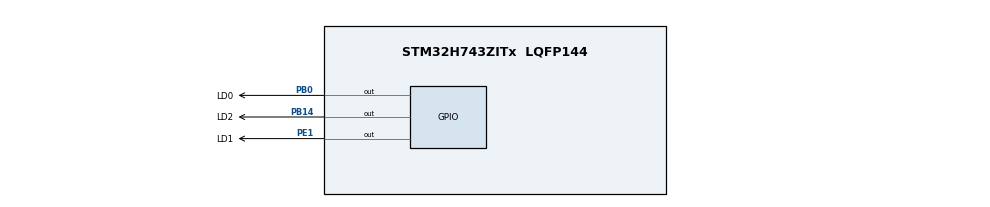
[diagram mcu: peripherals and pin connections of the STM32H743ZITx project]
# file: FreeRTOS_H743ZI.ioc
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Mcu.Family=STM32H7
Mcu.Name=STM32H743ZITx
Mcu.Package=LQFP144
NVIC.PriorityGroup=NVIC_PRIORITYGROUP_4
NVIC.TIM6_DAC_IRQn=true\:0\:0\:false\:true\:true\:2\:true\:true\:true
NVIC.TIM7_IRQn=true\:15\:0\:false\:false\:true\:false\:true\:true
NVIC.TimeBase=TIM7_IRQn
NVIC.TimeBaseIP=TIM7
PB0.GPIO_Label=LD0
PB0.GPIO_Speed=GPIO_SPEED_FREQ_VERY_HIGH
PB0.Signal=GPIO_Output
PB14.GPIO_Label=LD2
PB14.GPIO_Speed=GPIO_SPEED_FREQ_VERY_HIGH
PB14.Signal=GPIO_Output
PD8.Signal=USART3_TX
PD9.Signal=USART3_RX
PE1.GPIO_Label=LD1
PE1.GPIO_Speed=GPIO_SPEED_FREQ_VERY_HIGH
PE1.Signal=GPIO_Output
PH0-OSC_IN\ (PH0).Mode=HSE-External-Clock-Source
PH0-OSC_IN\ (PH0).Signal=RCC_OSC_IN
ProjectManager.HeapSize=0x200
ProjectManager.StackSize=0x400
ProjectManager.TargetToolchain=STM32CubeIDE
RCC.ADCFreq_Value=512000000
RCC.APB1Freq_Value=100000000
RCC.APB2Freq_Value=100000000
RCC.APB3Freq_Value=100000000
RCC.APB4Freq_Value=100000000
RCC.CortexFreq_Value=100000000
RCC.DIVM1=4
RCC.DIVM2=4
RCC.DIVM3=2
RCC.DIVN1=12
RCC.DIVN2=64
RCC.DIVN3=12
RCC.DIVQ3=30
RCC.HCLKFreq_Value=100000000
RCC.HSE_VALUE=25000000
RCC.PLL2FRACN=0
RCC.PLL2_VCI_Range-AdvancedSettings=RCC_PLL2VCIRANGE_3
RCC.PLL3FRACN=0
RCC.PLLFRACN=4096
RCC.PWR_Regulator_Voltage_Scale=PWR_REGULATOR_VOLTAGE_SCALE2
RCC.RCC_TIM_PRescaler_Selection=RCC_TIMPRES_ACTIVATED
RCC.SYSCLKFreq_VALUE=100000000
RCC.SYSCLKSource=RCC_SYSCLKSOURCE_PLLCLK
RCC.USART234578CLockSelection=RCC_USART234578CLKSOURCE_PLL3
RCC.USBFreq_Value=100000000
TIM6.AutoReloadPreload=TIM_AUTORELOAD_PRELOAD_DISABLE
TIM6.Period=100-1
TIM6.Prescaler=1000
VP_SYS_VS_tim7.Mode=TIM7
VP_TIM6_VS_ClockSourceINT.Mode=Enable_Timer
board=custom

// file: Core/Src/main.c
/* USER CODE BEGIN Header */
/**
  ******************************************************************************
  * @file           : main.c
  * @brief          : Main program body
  ******************************************************************************
  * @attention
  *
  * Copyright (c) 2026 STMicroelectronics.
  * All rights reserved.
  *
  * This software is licensed under terms that can be found in the LICENSE file
  * in the root directory of this software component.
  * If no LICENSE file comes with this software, it is provided AS-IS.
  *
  ******************************************************************************
  */
/* USER CODE END Header */
#include "main.h"

TIM_HandleTypeDef htim6;

/* USER CODE BEGIN PV */
#define STACK_SIZE 128

TaskHandle_t task1Handle;
TaskHandle_t task1Handle2;
TaskHandle_t task1Handle3;
/* USER CODE END PV */

void SystemClock_Config(void);
void PeriphCommonClock_Config(void);
static void MX_GPIO_Init(void);
static void MX_TIM6_Init(void);
static void MX_NVIC_Init(void);
/* USER CODE BEGIN PFP */
void vPortSetupTimerInterrupt(void)
{
	// Do not use sysTick timer for freRTOS, Created the timer TIM6 for it.
}
/* USER CODE END PFP */

/* USER CODE BEGIN 0 */
void monitorTask(void *para)
{
	uint8_t val = 0;
	bool Stat = false;
	TimeOut_t RefTimet;
	TickType_t RequiredTimet = 5000;

	vTaskSetTimeOutState(&RefTimet);
  while(1)
  {
	if(xTaskCheckForTimeOut(&RefTimet, &RequiredTimet) == pdTRUE)
	{
		// Timeout occured
		vTaskSetTimeOutState(&RefTimet);
		RequiredTimet = 5000;
	}
	vTaskDelay(pdMS_TO_TICKS(100));
	// Previosly not running because this task was the highest priority and it occupied the total CPU usage by
	// poling for the status "xTaskCheckForTimeOut()". So We added the delay "vTaskDelay" and lets the other
	// tasks occupied the CPU whenever this task is not doing anything. Of course this is the demo code so we can add
	// delay to make things understanding but in actual application we might apply some thing professional.
  }
}

void Task2 (void* para)
{
	BaseType_t delaystate;

	TickType_t tickCount = xTaskGetTickCount();
	while(1)
	{
		delaystate = xTaskDelayUntil(&tickCount, pdMS_TO_TICKS(1000));
		if(delaystate == pdTRUE)
		{
			HAL_GPIO_TogglePin(LD0_GPIO_Port, LD0_Pin);
		}
	}
}

void Task3 (void* para)
{
	BaseType_t delaystate;

	TickType_t tickCount = xTaskGetTickCount();
	while(1)
	{
		delaystate = xTaskDelayUntil(&tickCount, pdMS_TO_TICKS(500));
		if(delaystate == pdTRUE)
		{
			HAL_GPIO_TogglePin(LD1_GPIO_Port, LD1_Pin);
		}
	}
}
//Successfully Ported..
/* USER CODE END 0 */

int main(void)
{

  /* MCU Configuration--------------------------------------------------------*/

  /* Reset of all peripherals, Initializes the Flash interface and the Systick. */
  HAL_Init();

  /* Configure the system clock */
  SystemClock_Config();

/* Configure the peripherals common clocks */
  PeriphCommonClock_Config();

  /* Initialize all configured peripherals */
  MX_GPIO_Init();
  MX_TIM6_Init();

  /* Initialize interrupts */
  MX_NVIC_Init();
  /* USER CODE BEGIN 2 */
#if 1
  if(xTaskCreate(monitorTask,
  			"SampleTask",
  			STACK_SIZE,
  			NULL,
  			tskIDLE_PRIORITY + 4,
  			&task1Handle) == pdFAIL)
  	{
  	// Task created
  		while(1);
  	}

  	if(xTaskCreate(Task2,
  				"Task2",
  				STACK_SIZE,
  				NULL,
  				tskIDLE_PRIORITY + 2,
  				&task1Handle2) == pdFAIL)
  	{
  		while(1);
  	}

  	if(xTaskCreate(Task3,
  				"Task3",
  				STACK_SIZE,
  				NULL,
  				tskIDLE_PRIORITY + 1,
  				&task1Handle3) == pdFAIL)
  	{
  		while(1);
  	}

  	vTaskStartScheduler();
#endif
  /* USER CODE END 2 */

  /* Infinite loop */
  /* USER CODE BEGIN WHILE */
  while (1)
  {
	  //HAL_GPIO_TogglePin(LD0_GPIO_Port, LD0_Pin);
	  //HAL_GPIO_TogglePin(LD1_GPIO_Port, LD1_Pin);
	  //HAL_GPIO_TogglePin(LD2_GPIO_Port, LD2_Pin);
	  HAL_Delay(500);
    /* USER CODE END WHILE */

  }
}

void SystemClock_Config(void)
{
  RCC_OscInitTypeDef RCC_OscInitStruct = {0};
  RCC_ClkInitTypeDef RCC_ClkInitStruct = {0};

  /** Supply configuration update enable
  */
  HAL_PWREx_ConfigSupply(PWR_LDO_SUPPLY);

  /** Configure the main internal regulator output voltage
  */
  __HAL_PWR_VOLTAGESCALING_CONFIG(PWR_REGULATOR_VOLTAGE_SCALE2);

  while(!__HAL_PWR_GET_FLAG(PWR_FLAG_VOSRDY)) {}

  /** Initializes the RCC Oscillators according to the specified parameters
  * in the RCC_OscInitTypeDef structure.
  */
  RCC_OscInitStruct.OscillatorType = RCC_OSCILLATORTYPE_HSI;
  RCC_OscInitStruct.HSIState = RCC_HSI_DIV1;
  RCC_OscInitStruct.HSICalibrationValue = RCC_HSICALIBRATION_DEFAULT;
  RCC_OscInitStruct.PLL.PLLState = RCC_PLL_ON;
  RCC_OscInitStruct.PLL.PLLSource = RCC_PLLSOURCE_HSI;
  RCC_OscInitStruct.PLL.PLLM = 4;
  RCC_OscInitStruct.PLL.PLLN = 12;
  RCC_OscInitStruct.PLL.PLLP = 2;
  RCC_OscInitStruct.PLL.PLLQ = 2;
  RCC_OscInitStruct.PLL.PLLR = 2;
  RCC_OscInitStruct.PLL.PLLRGE = RCC_PLL1VCIRANGE_3;
  RCC_OscInitStruct.PLL.PLLVCOSEL = RCC_PLL1VCOWIDE;
  RCC_OscInitStruct.PLL.PLLFRACN = 4096;
  if (HAL_RCC_OscConfig(&RCC_OscInitStruct) != HAL_OK)
  {
    Error_Handler();
  }

  /** Initializes the CPU, AHB and APB buses clocks
  */
  RCC_ClkInitStruct.ClockType = RCC_CLOCKTYPE_HCLK|RCC_CLOCKTYPE_SYSCLK
                              |RCC_CLOCKTYPE_PCLK1|RCC_CLOCKTYPE_PCLK2
                              |RCC_CLOCKTYPE_D3PCLK1|RCC_CLOCKTYPE_D1PCLK1;
  RCC_ClkInitStruct.SYSCLKSource = RCC_SYSCLKSOURCE_PLLCLK;
  RCC_ClkInitStruct.SYSCLKDivider = RCC_SYSCLK_DIV1;
  RCC_ClkInitStruct.AHBCLKDivider = RCC_HCLK_DIV1;
  RCC_ClkInitStruct.APB3CLKDivider = RCC_APB3_DIV1;
  RCC_ClkInitStruct.APB1CLKDivider = RCC_APB1_DIV1;
  RCC_ClkInitStruct.APB2CLKDivider = RCC_APB2_DIV1;
  RCC_ClkInitStruct.APB4CLKDivider = RCC_APB4_DIV1;

  if (HAL_RCC_ClockConfig(&RCC_ClkInitStruct, FLASH_LATENCY_1) != HAL_OK)
  {
    Error_Handler();
  }
}

void PeriphCommonClock_Config(void)
{
  RCC_PeriphCLKInitTypeDef PeriphClkInitStruct = {0};

  /** Initializes the peripherals clock
  */
  PeriphClkInitStruct.PeriphClockSelection = RCC_PERIPHCLK_TIM;
  PeriphClkInitStruct.TIMPresSelection = RCC_TIMPRES_ACTIVATED;

  if (HAL_RCCEx_PeriphCLKConfig(&PeriphClkInitStruct) != HAL_OK)
  {
    Error_Handler();
  }
}

/**
  * @brief NVIC Configuration.
  * @retval None
  */
static void MX_NVIC_Init(void)
{
  /* TIM6_DAC_IRQn interrupt configuration */
  HAL_NVIC_SetPriority(TIM6_DAC_IRQn, 0, 0);
  HAL_NVIC_EnableIRQ(TIM6_DAC_IRQn);
}

static void MX_TIM6_Init(void)
{

  TIM_MasterConfigTypeDef sMasterConfig = {0};

  htim6.Instance = TIM6;
  htim6.Init.Prescaler = 1000;
  htim6.Init.CounterMode = TIM_COUNTERMODE_UP;
  htim6.Init.Period = 100-1;
  htim6.Init.AutoReloadPreload = TIM_AUTORELOAD_PRELOAD_DISABLE;
  if (HAL_TIM_Base_Init(&htim6) != HAL_OK)
  {
    Error_Handler();
  }
  sMasterConfig.MasterOutputTrigger = TIM_TRGO_RESET;
  sMasterConfig.MasterSlaveMode = TIM_MASTERSLAVEMODE_DISABLE;
  if (HAL_TIMEx_MasterConfigSynchronization(&htim6, &sMasterConfig) != HAL_OK)
  {
    Error_Handler();
  }
  /* USER CODE BEGIN TIM6_Init 2 */
  HAL_TIM_Base_Start_IT(&htim6);
  /* USER CODE END TIM6_Init 2 */

}

static void MX_GPIO_Init(void)
{
  GPIO_InitTypeDef GPIO_InitStruct = {0};

  /* GPIO Ports Clock Enable */
  __HAL_RCC_GPIOH_CLK_ENABLE();
  __HAL_RCC_GPIOB_CLK_ENABLE();
  __HAL_RCC_GPIOD_CLK_ENABLE();
  __HAL_RCC_GPIOE_CLK_ENABLE();

  /*Configure GPIO pin Output Level */
  HAL_GPIO_WritePin(GPIOB, LD0_Pin|LD2_Pin, GPIO_PIN_RESET);

  /*Configure GPIO pin Output Level */
  HAL_GPIO_WritePin(LD1_GPIO_Port, LD1_Pin, GPIO_PIN_RESET);

  /*Configure GPIO pins : LD0_Pin LD2_Pin */
  GPIO_InitStruct.Pin = LD0_Pin|LD2_Pin;
  GPIO_InitStruct.Mode = GPIO_MODE_OUTPUT_PP;
  GPIO_InitStruct.Pull = GPIO_NOPULL;
  GPIO_InitStruct.Speed = GPIO_SPEED_FREQ_VERY_HIGH;
  HAL_GPIO_Init(GPIOB, &GPIO_InitStruct);

  /*Configure GPIO pins : PD8 PD9 */
  GPIO_InitStruct.Pin = GPIO_PIN_8|GPIO_PIN_9;
  GPIO_InitStruct.Mode = GPIO_MODE_AF_PP;
  GPIO_InitStruct.Pull = GPIO_NOPULL;
  GPIO_InitStruct.Speed = GPIO_SPEED_FREQ_LOW;
  GPIO_InitStruct.Alternate = GPIO_AF7_USART3;
  HAL_GPIO_Init(GPIOD, &GPIO_InitStruct);

  /*Configure GPIO pin : LD1_Pin */
  GPIO_InitStruct.Pin = LD1_Pin;
  GPIO_InitStruct.Mode = GPIO_MODE_OUTPUT_PP;
  GPIO_InitStruct.Pull = GPIO_NOPULL;
  GPIO_InitStruct.Speed = GPIO_SPEED_FREQ_VERY_HIGH;
  HAL_GPIO_Init(LD1_GPIO_Port, &GPIO_InitStruct);

}

/* USER CODE BEGIN 4 */
void vApplicationStackOverflowHook(TaskHandle_t xTask, char *pcTaskName) {
    // Trigger a breakpoint or reset the system here
    while (1) {
		//GPIO_TogglePin(GPIOC, GPIO_PIN_9);
			//Delay_ms(1000);
	}
}

#if (configUSE_IDLE_HOOK == 1)
void vApplicationIdleHook(void) {
    // This runs whenever no other task is ready to run
    // Enter Sleep Mode
    //__WFI();
    		//GPIO_TogglePin(GPIOC, GPIO_PIN_8);
            //Delay_ms(10);
	while(1);
}
#endif

void vApplicationMallocFailedHook(void)
{
    while(1)
    {
        /* Memory exhausted */
    	while(1);
    }
}
/* USER CODE END 4 */

void HAL_TIM_PeriodElapsedCallback(TIM_HandleTypeDef *htim)
{
  /* USER CODE BEGIN Callback 0 */
	static volatile int dat = 0;
  /* USER CODE END Callback 0 */
  if (htim->Instance == TIM7) {
    HAL_IncTick();
  }
  /* USER CODE BEGIN Callback 1 */

  if(htim->Instance == TIM6)
  {
	  //HAL_GPIO_TogglePin(LD2_GPIO_Port, LD2_Pin);
		dat++;
		if(dat > 1000)
		{
			dat = 0;
			HAL_GPIO_TogglePin(LD2_GPIO_Port, LD2_Pin);
		}
#if 1
	if (xTaskGetSchedulerState() != taskSCHEDULER_NOT_STARTED) {
	  /* Call tick handler */
		xPortSysTickHandler();
	}
#endif
  }
  /* USER CODE END Callback 1 */
}

void Error_Handler(void)
{
  __disable_irq();
  while (1)
  {
  }
}
